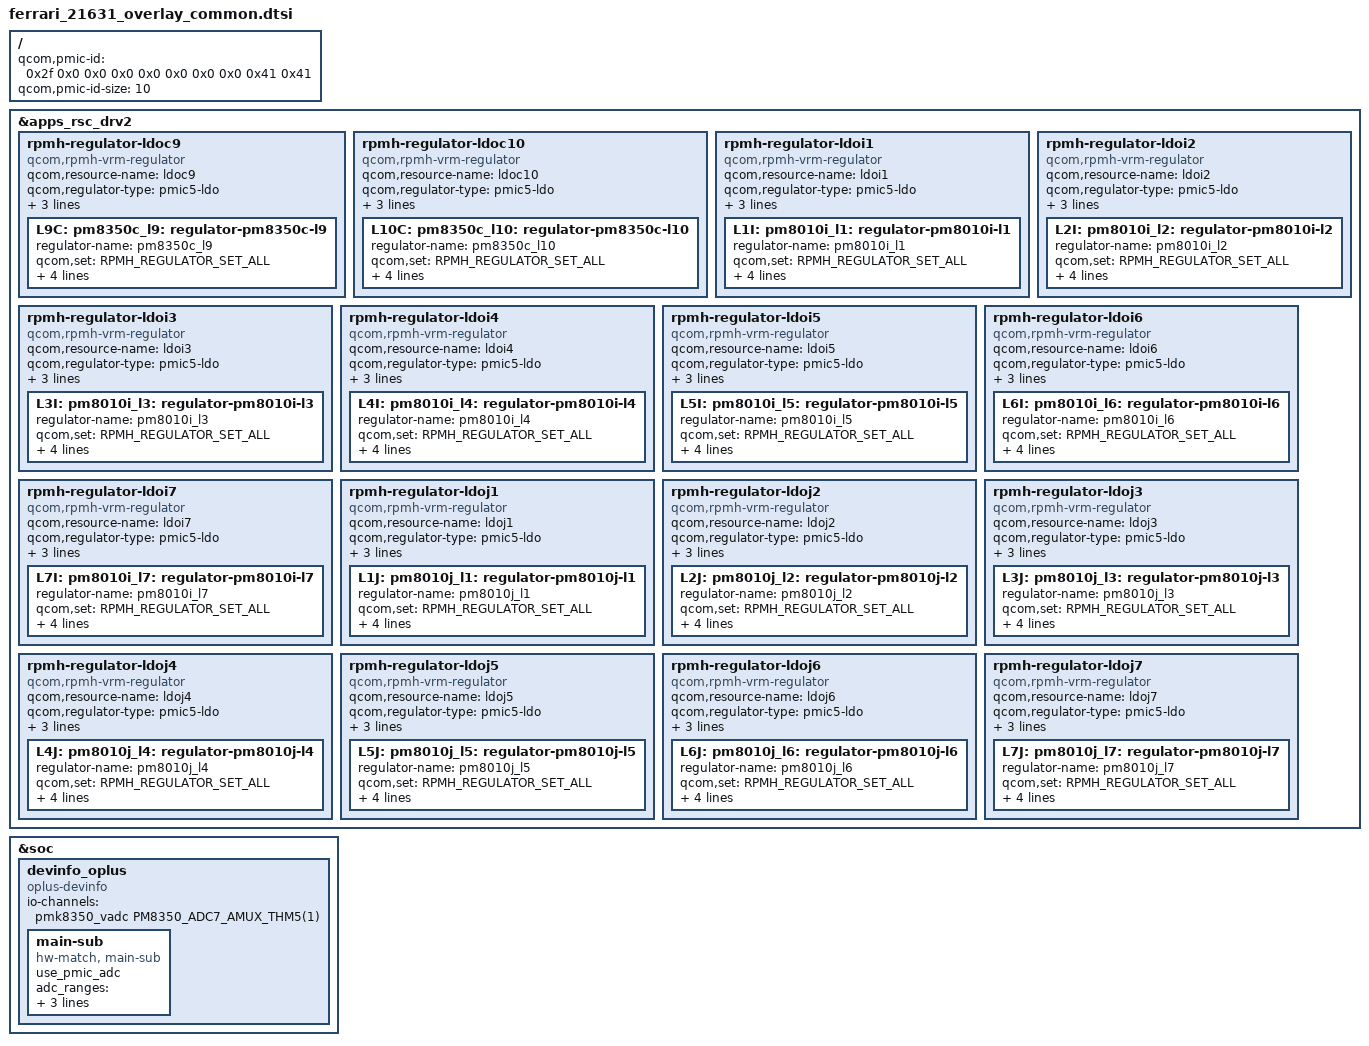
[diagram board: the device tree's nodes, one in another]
/* Waipio configurations for PM8010I and PM8010J connected via SPMI */

#include <dt-bindings/regulator/qcom,rpmh-regulator-levels.h>

/ {
	qcom,pmic-id = <0x2f 0x0 0x0 0x0 0x0 0x0 0x0 0x0 0x41 0x41>;
	qcom,pmic-id-size = <10>;
};

&apps_rsc_drv2 {

    rpmh-regulator-ldoc9 {
		compatible = "qcom,rpmh-vrm-regulator";
		qcom,resource-name = "ldoc9";
		qcom,regulator-type = "pmic5-ldo";
		qcom,supported-modes =
			<RPMH_REGULATOR_MODE_LPM
			 RPMH_REGULATOR_MODE_HPM>;
		qcom,mode-threshold-currents = <0 10000>;
		L9C: pm8350c_l9: regulator-pm8350c-l9 {
			regulator-name = "pm8350c_l9";
			qcom,set = <RPMH_REGULATOR_SET_ALL>;
			regulator-min-microvolt = <2800000>;
			regulator-max-microvolt = <3008000>;
			qcom,init-voltage = <2800000>;
			qcom,init-mode = <RPMH_REGULATOR_MODE_HPM>;
		};
	};

    rpmh-regulator-ldoc10 {
		compatible = "qcom,rpmh-vrm-regulator";
		qcom,resource-name = "ldoc10";
		qcom,regulator-type = "pmic5-ldo";
		qcom,supported-modes =
			<RPMH_REGULATOR_MODE_LPM
			 RPMH_REGULATOR_MODE_HPM>;
		qcom,mode-threshold-currents = <0 30000>;
		L10C: pm8350c_l10: regulator-pm8350c-l10 {
			regulator-name = "pm8350c_l10";
			qcom,set = <RPMH_REGULATOR_SET_ALL>;
			regulator-min-microvolt = <1104000>;
			regulator-max-microvolt = <1104000>;
			qcom,init-voltage = <1104000>;
			qcom,init-mode = <RPMH_REGULATOR_MODE_HPM>;
		};
	};

	rpmh-regulator-ldoi1 {
	    compatible = "qcom,rpmh-vrm-regulator";
	    qcom,resource-name = "ldoi1";
	    qcom,regulator-type = "pmic5-ldo";
	    qcom,supported-modes =
	        <RPMH_REGULATOR_MODE_LPM
	         RPMH_REGULATOR_MODE_HPM>;
	    qcom,mode-threshold-currents = <0 30000>;
	    L1I: pm8010i_l1: regulator-pm8010i-l1 {
	        regulator-name = "pm8010i_l1";
	        qcom,set = <RPMH_REGULATOR_SET_ALL>;
	        regulator-min-microvolt = <1104000>;
	        regulator-max-microvolt = <1204000>;
	        qcom,init-voltage = <1150000>;
	        qcom,init-mode = <RPMH_REGULATOR_MODE_HPM>;
	    };
	};

	rpmh-regulator-ldoi2 {
		compatible = "qcom,rpmh-vrm-regulator";
		qcom,resource-name = "ldoi2";
		qcom,regulator-type = "pmic5-ldo";
		qcom,supported-modes =
			<RPMH_REGULATOR_MODE_LPM
			 RPMH_REGULATOR_MODE_HPM>;
		qcom,mode-threshold-currents = <0 30000>;
		L2I: pm8010i_l2: regulator-pm8010i-l2 {
			regulator-name = "pm8010i_l2";
			qcom,set = <RPMH_REGULATOR_SET_ALL>;
			regulator-min-microvolt = <1056000>;
			regulator-max-microvolt = <1260000>;
			qcom,init-voltage = <1056000>;
			qcom,init-mode = <RPMH_REGULATOR_MODE_HPM>;
		};
	};

	rpmh-regulator-ldoi3 {
		compatible = "qcom,rpmh-vrm-regulator";
		qcom,resource-name = "ldoi3";
		qcom,regulator-type = "pmic5-ldo";
		qcom,supported-modes =
			<RPMH_REGULATOR_MODE_LPM
			 RPMH_REGULATOR_MODE_HPM>;
		qcom,mode-threshold-currents = <0 10000>;
		L3I: pm8010i_l3: regulator-pm8010i-l3 {
			regulator-name = "pm8010i_l3";
			qcom,set = <RPMH_REGULATOR_SET_ALL>;
			regulator-min-microvolt = <2700000>;
			regulator-max-microvolt = <2904000>;
			qcom,init-voltage = <2800000>;
			qcom,init-mode = <RPMH_REGULATOR_MODE_HPM>;
		};
	};

	rpmh-regulator-ldoi4 {
		compatible = "qcom,rpmh-vrm-regulator";
		qcom,resource-name = "ldoi4";
		qcom,regulator-type = "pmic5-ldo";
		qcom,supported-modes =
			<RPMH_REGULATOR_MODE_LPM
			 RPMH_REGULATOR_MODE_HPM>;
		qcom,mode-threshold-currents = <0 10000>;
		L4I: pm8010i_l4: regulator-pm8010i-l4 {
			regulator-name = "pm8010i_l4";
			qcom,set = <RPMH_REGULATOR_SET_ALL>;
			regulator-min-microvolt = <2800000>;
			regulator-max-microvolt = <3304000>;
			qcom,init-voltage = <3150000>;
			qcom,init-mode = <RPMH_REGULATOR_MODE_HPM>;
		};
	};
	rpmh-regulator-ldoi5 {
	    compatible = "qcom,rpmh-vrm-regulator";
	    qcom,resource-name = "ldoi5";
	    qcom,regulator-type = "pmic5-ldo";
	    qcom,supported-modes =
	        <RPMH_REGULATOR_MODE_LPM
	         RPMH_REGULATOR_MODE_HPM>;
	    qcom,mode-threshold-currents = <0 10000>;
	    L5I: pm8010i_l5: regulator-pm8010i-l5 {
	        regulator-name = "pm8010i_l5";
	        qcom,set = <RPMH_REGULATOR_SET_ALL>;
	        regulator-min-microvolt = <1800000>;
	        regulator-max-microvolt = <2800000>;
	        qcom,init-voltage = <1800000>;
	        qcom,init-mode = <RPMH_REGULATOR_MODE_HPM>;
	    };
	};

	rpmh-regulator-ldoi6 {
		compatible = "qcom,rpmh-vrm-regulator";
		qcom,resource-name = "ldoi6";
		qcom,regulator-type = "pmic5-ldo";
		qcom,supported-modes =
			<RPMH_REGULATOR_MODE_LPM
			 RPMH_REGULATOR_MODE_HPM>;
		qcom,mode-threshold-currents = <0 10000>;
		L6I: pm8010i_l6: regulator-pm8010i-l6 {
			regulator-name = "pm8010i_l6";
			qcom,set = <RPMH_REGULATOR_SET_ALL>;
			regulator-min-microvolt = <2800000>;
			regulator-max-microvolt = <3304000>;
			qcom,init-voltage = <3150000>;
			qcom,init-mode = <RPMH_REGULATOR_MODE_HPM>;
		};
	};

	rpmh-regulator-ldoi7 {
		compatible = "qcom,rpmh-vrm-regulator";
		qcom,resource-name = "ldoi7";
		qcom,regulator-type = "pmic5-ldo";
		qcom,supported-modes =
			<RPMH_REGULATOR_MODE_LPM
			 RPMH_REGULATOR_MODE_HPM>;
		qcom,mode-threshold-currents = <0 10000>;
		L7I: pm8010i_l7: regulator-pm8010i-l7 {
			regulator-name = "pm8010i_l7";
			qcom,set = <RPMH_REGULATOR_SET_ALL>;
			regulator-min-microvolt = <1800000>;
			regulator-max-microvolt = <2960000>;
			qcom,init-voltage = <1800000>;
			qcom,init-mode = <RPMH_REGULATOR_MODE_HPM>;
		};
	};

	rpmh-regulator-ldoj1 {
		compatible = "qcom,rpmh-vrm-regulator";
		qcom,resource-name = "ldoj1";
		qcom,regulator-type = "pmic5-ldo";
		qcom,supported-modes =
			<RPMH_REGULATOR_MODE_LPM
			 RPMH_REGULATOR_MODE_HPM>;
		qcom,mode-threshold-currents = <0 30000>;
		L1J: pm8010j_l1: regulator-pm8010j-l1 {
			regulator-name = "pm8010j_l1";
			qcom,set = <RPMH_REGULATOR_SET_ALL>;
			regulator-min-microvolt = <1104000>;
			regulator-max-microvolt = <1204000>;
			qcom,init-voltage = <1104000>;
			qcom,init-mode = <RPMH_REGULATOR_MODE_HPM>;
		};
	};

	rpmh-regulator-ldoj2 {
		compatible = "qcom,rpmh-vrm-regulator";
		qcom,resource-name = "ldoj2";
		qcom,regulator-type = "pmic5-ldo";
		qcom,supported-modes =
			<RPMH_REGULATOR_MODE_LPM
			 RPMH_REGULATOR_MODE_HPM>;
		qcom,mode-threshold-currents = <0 30000>;
		L2J: pm8010j_l2: regulator-pm8010j-l2 {
			regulator-name = "pm8010j_l2";
			qcom,set = <RPMH_REGULATOR_SET_ALL>;
			regulator-min-microvolt = <800000>;
			regulator-max-microvolt = <1056000>;
			qcom,init-voltage = <810000>;
			qcom,init-mode = <RPMH_REGULATOR_MODE_HPM>;
		};
	};

	rpmh-regulator-ldoj3 {
		compatible = "qcom,rpmh-vrm-regulator";
		qcom,resource-name = "ldoj3";
		qcom,regulator-type = "pmic5-ldo";
		qcom,supported-modes =
			<RPMH_REGULATOR_MODE_LPM
			 RPMH_REGULATOR_MODE_HPM>;
		qcom,mode-threshold-currents = <0 10000>;
		L3J: pm8010j_l3: regulator-pm8010j-l3 {
			regulator-name = "pm8010j_l3";
			qcom,set = <RPMH_REGULATOR_SET_ALL>;
			regulator-min-microvolt = <1800000>;
			regulator-max-microvolt = <2904000>;
			qcom,init-voltage = <2800000>;
			qcom,init-mode = <RPMH_REGULATOR_MODE_HPM>;
		};
	};

	rpmh-regulator-ldoj4 {
		compatible = "qcom,rpmh-vrm-regulator";
		qcom,resource-name = "ldoj4";
		qcom,regulator-type = "pmic5-ldo";
		qcom,supported-modes =
			<RPMH_REGULATOR_MODE_LPM
			 RPMH_REGULATOR_MODE_HPM>;
		qcom,mode-threshold-currents = <0 10000>;
		L4J: pm8010j_l4: regulator-pm8010j-l4 {
			regulator-name = "pm8010j_l4";
			qcom,set = <RPMH_REGULATOR_SET_ALL>;
			regulator-min-microvolt = <2800000>;
			regulator-max-microvolt = <3008000>;
			qcom,init-voltage = <2904000>;
			qcom,init-mode = <RPMH_REGULATOR_MODE_HPM>;
		};
	};

	rpmh-regulator-ldoj5 {
		compatible = "qcom,rpmh-vrm-regulator";
		qcom,resource-name = "ldoj5";
		qcom,regulator-type = "pmic5-ldo";
		qcom,supported-modes =
			<RPMH_REGULATOR_MODE_LPM
			 RPMH_REGULATOR_MODE_HPM>;
		qcom,mode-threshold-currents = <0 10000>;
		L5J: pm8010j_l5: regulator-pm8010j-l5 {
			regulator-name = "pm8010j_l5";
			qcom,set = <RPMH_REGULATOR_SET_ALL>;
			regulator-min-microvolt = <1800000>;
			regulator-max-microvolt = <2800000>;
			qcom,init-voltage = <1800000>;
			qcom,init-mode = <RPMH_REGULATOR_MODE_HPM>;
		};
	};

	rpmh-regulator-ldoj6 {
		compatible = "qcom,rpmh-vrm-regulator";
		qcom,resource-name = "ldoj6";
		qcom,regulator-type = "pmic5-ldo";
		qcom,supported-modes =
			<RPMH_REGULATOR_MODE_LPM
			 RPMH_REGULATOR_MODE_HPM>;
		qcom,mode-threshold-currents = <0 10000>;
		L6J: pm8010j_l6: regulator-pm8010j-l6 {
			regulator-name = "pm8010j_l6";
			qcom,set = <RPMH_REGULATOR_SET_ALL>;
			regulator-min-microvolt = <2800000>;
			regulator-max-microvolt = <2800000>;
			qcom,init-voltage = <2800000>;
			qcom,init-mode = <RPMH_REGULATOR_MODE_HPM>;
		};
	};

	rpmh-regulator-ldoj7 {
		compatible = "qcom,rpmh-vrm-regulator";
		qcom,resource-name = "ldoj7";
		qcom,regulator-type = "pmic5-ldo";
		qcom,supported-modes =
			<RPMH_REGULATOR_MODE_LPM
			 RPMH_REGULATOR_MODE_HPM>;
		qcom,mode-threshold-currents = <0 10000>;
		L7J: pm8010j_l7: regulator-pm8010j-l7 {
			regulator-name = "pm8010j_l7";
			qcom,set = <RPMH_REGULATOR_SET_ALL>;
			regulator-min-microvolt = <2800000>;
			regulator-max-microvolt = <3304000>;
			qcom,init-voltage = <2800000>;
			qcom,init-mode = <RPMH_REGULATOR_MODE_HPM>;
		};
	};
};
&soc {

	devinfo_oplus {
		compatible = "oplus-devinfo";

		io-channels= <&pmk8350_vadc PM8350_ADC7_AMUX_THM5(1)>;
		io-channel-names= "vph_pwr_voltage_sub";

		main-sub {
			compatible = "hw-match, main-sub";
			use_pmic_adc;
			adc_ranges = <0 80
					81 180
					181 300
					301 420
					421 550
					551 650
					651 760
					761 850
					851 950
					951 1050
					1051 1150
					1151 1300>;
			aboard-patterns = <0 0>;

			/*main board*/
			match-projects = <21631 0x216AC>;
		};
	};

};
